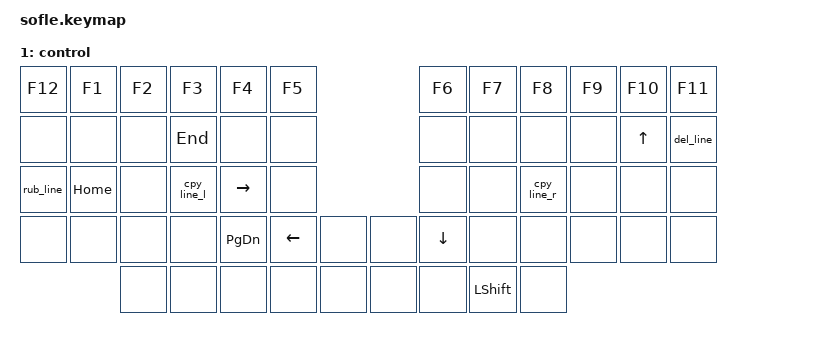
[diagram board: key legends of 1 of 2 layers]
#include <dt-bindings/zmk/behaviors.h>
#include <behaviors.dtsi>
#include <dt-bindings/zmk/bt.h>
#include <dt-bindings/zmk/keys.h>

#define HRL(k1,k2,k3) &ht LGUI k1  &ht LALT k2  &ht LCTRL k3
#define HRR(k1,k2,k3) &ht RCTRL k1 &ht RALT k2  &ht RGUI k3

/ {
    macros {
        cpy_line_r: cpy_line_r {
            compatible = "zmk,behavior-macro";
            #binding-cells = <0>;
            bindings =
                <&macro_tap &kp LS(END)>,
                <&macro_tap &kp LC(C)>,
                <&macro_tap &kp LEFT>;
        };
        del_line: del_line {
            compatible = "zmk,behavior-macro";
            #binding-cells = <0>;
            bindings =
                <&macro_tap &kp LS(END)>,
                <&macro_tap &kp DEL>;
        };
        cpy_line_l: cpy_line_l {
            compatible = "zmk,behavior-macro";
            #binding-cells = <0>;
            bindings =
                <&macro_tap &kp LS(HOME)>,
                <&macro_tap &kp LC(C)>,
                <&macro_tap &kp RIGHT>;
        };
        rub_line: rub_line {
            compatible = "zmk,behavior-macro";
            #binding-cells = <0>;
            bindings =
                <&macro_tap &kp LS(HOME)>,
                <&macro_tap &kp BSPC>;
        };
    };

    behaviors {
        ht: hold_tap {
            compatible = "zmk,behavior-hold-tap";
            #binding-cells = <2>;
            flavor = "tap-preferred";
            tapping-term-ms = <220>;
            quick-tap-ms = <150>;
            require-prior-idle-ms = <100>;
            bindings = <&kp>, <&kp>;
        };
    };

    keymap {
        compatible = "zmk,keymap";

        default_layer {
            display-name = "Default";
            bindings = <
&kp EQUAL     &kp N1     &kp N2       &kp N3        &kp N4      &kp N5                         &kp N6     &kp N7     &kp N8      &kp N9    &kp N0      &kp GRAVE
&kp TAB       &kp Q      &kp W        &kp E         &kp R       &kp T                          &kp Y      &kp U      &kp I       &kp O     &kp P       &none
&none         &kp A      HRL(S,       D,            F)          &kp G                          &kp H      HRR(J,     K,          L)        &kp SEMI    &none
&kp ESC       &kp Z      &kp X        &kp C         &kp V       &kp B      &none     &none     &kp N      &kp M      &kp COMMA   &kp DOT   &kp SLASH   &kp BSLH
                         &kp MINUS    &kp LBKT      &kp BSPC    &kp LSHFT  &kp DEL   &kp RET   &kp SPACE  &mo 1      &kp RBKT    &kp SQT
            >;

            sensor-bindings = <&inc_dec_kp C_VOL_UP C_VOL_DN &inc_dec_kp PG_UP PG_DN>;
        };
control {
            display-name = "control";
            bindings = <
&kp F12       &kp F1     &kp F2       &kp F3        &kp F4      &kp F5                      &kp F6     &kp F7     &kp F8      &kp F9    &kp F10      &kp F11
&none         &none      &none          &kp END      &none        &none                      &none      &none      &none         &none        &kp UP        &del_line
&rub_line     &kp HOME   &none          &cpy_line_l  &kp RIGHT    &none                      &none      &none      &cpy_line_r   &none    &none  &none
&none         &none      &none          &none        &kp PG_DN    &kp LEFT    &none &none    &kp DOWN   &none      &none        &none       &none     &none
                         &none          &none        &none        &none       &none &none    &none      &kp LSHFT  &none
            >;
        };
    };
};
